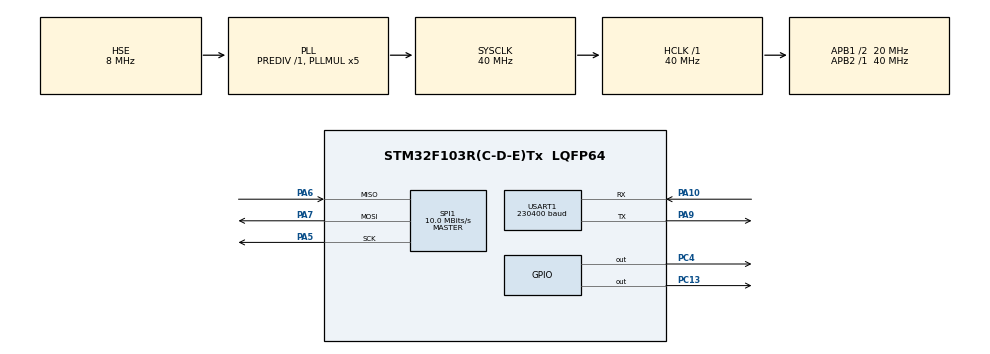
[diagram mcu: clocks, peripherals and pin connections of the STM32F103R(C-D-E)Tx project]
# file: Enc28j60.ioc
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Mcu.Family=STM32F1
Mcu.Name=STM32F103R(C-D-E)Tx
Mcu.Package=LQFP64
NVIC.PriorityGroup=NVIC_PRIORITYGROUP_4
NVIC.TIM2_IRQn=true\:0\:0\:false\:false\:true\:true\:true
NVIC.USART1_IRQn=true\:0\:0\:false\:false\:true\:true\:true
PA10.Mode=Asynchronous
PA10.Signal=USART1_RX
PA13.Mode=Serial_Wire
PA13.Signal=SYS_JTMS-SWDIO
PA14.Mode=Serial_Wire
PA14.Signal=SYS_JTCK-SWCLK
PA5.Mode=Full_Duplex_Master
PA5.Signal=SPI1_SCK
PA6.Mode=Full_Duplex_Master
PA6.Signal=SPI1_MISO
PA7.Mode=Full_Duplex_Master
PA7.Signal=SPI1_MOSI
PA9.Mode=Asynchronous
PA9.Signal=USART1_TX
PC13-TAMPER-RTC.GPIO_Speed=GPIO_SPEED_FREQ_MEDIUM
PC13-TAMPER-RTC.Signal=GPIO_Output
PC4.Signal=GPIO_Output
PD0-OSC_IN.Mode=HSE-External-Oscillator
PD0-OSC_IN.Signal=RCC_OSC_IN
PD1-OSC_OUT.Mode=HSE-External-Oscillator
PD1-OSC_OUT.Signal=RCC_OSC_OUT
ProjectManager.HeapSize=0x200
ProjectManager.StackSize=0x400
ProjectManager.TargetToolchain=MDK-ARM V5.27
RCC.AHBFreq_Value=40000000
RCC.APB1CLKDivider=RCC_HCLK_DIV2
RCC.APB1Freq_Value=20000000
RCC.APB1TimFreq_Value=40000000
RCC.APB2Freq_Value=40000000
RCC.APB2TimFreq_Value=40000000
RCC.HCLKFreq_Value=40000000
RCC.PLLMUL=RCC_PLL_MUL5
RCC.PLLSourceVirtual=RCC_PLLSOURCE_HSE
RCC.SYSCLKFreq_VALUE=40000000
RCC.SYSCLKSource=RCC_SYSCLKSOURCE_PLLCLK
RCC.USBFreq_Value=40000000
SPI1.BaudRatePrescaler=SPI_BAUDRATEPRESCALER_4
SPI1.CalculateBaudRate=10.0 MBits/s
SPI1.Direction=SPI_DIRECTION_2LINES
SPI1.Mode=SPI_MODE_MASTER
SPI1.VirtualType=VM_MASTER
TIM2.Period=1000
TIM2.Prescaler=39999
TIM2.TIM_MasterOutputTrigger=TIM_TRGO_UPDATE
USART1.BaudRate=230400
USART1.VirtualMode=VM_ASYNC
VP_TIM2_VS_ClockSourceINT.Mode=Internal
board=custom

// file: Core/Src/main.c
/* USER CODE BEGIN Header */
/**
  ******************************************************************************
  * @file           : main.c
  * @brief          : Main program body
  ******************************************************************************
  * @attention
  *
  * <h2><center>&copy; Copyright (c) 2021 STMicroelectronics.
  * All rights reserved.</center></h2>
  *
  * This software component is licensed by ST under BSD 3-Clause license,
  * the "License"; You may not use this file except in compliance with the
  * License. You may obtain a copy of the License at:
  *                        opensource.org/licenses/BSD-3-Clause
  *
  ******************************************************************************
  */
/* USER CODE END Header */
#include "main.h"

/* USER CODE BEGIN Includes */
#include "net.h"
#include "enc28j60.h"
/* USER CODE END Includes */

SPI_HandleTypeDef hspi1;

TIM_HandleTypeDef htim2;

UART_HandleTypeDef huart1;

/* USER CODE BEGIN PV */
char str[20];
/* USER CODE END PV */

void SystemClock_Config(void);
static void MX_GPIO_Init(void);
static void MX_SPI1_Init(void);
static void MX_USART1_UART_Init(void);
static void MX_TIM2_Init(void);

int main(void)
{

  /* MCU Configuration--------------------------------------------------------*/

  /* Reset of all peripherals, Initializes the Flash interface and the Systick. */
  HAL_Init();

  /* Configure the system clock */
  SystemClock_Config();

  /* Initialize all configured peripherals */
  MX_GPIO_Init();
  MX_SPI1_Init();
  MX_USART1_UART_Init();
  MX_TIM2_Init();
  /* USER CODE BEGIN 2 */
	net_ini();
	HAL_UART_Receive_IT(&huart1,(uint8_t*)str,1);
	HAL_TIM_Base_Start_IT(&htim2);
  /* USER CODE END 2 */

  /* Infinite loop */
  /* USER CODE BEGIN WHILE */
  while (1)
  {
		net_pool();
    /* USER CODE END WHILE */

  }
}

void SystemClock_Config(void)
{
  RCC_OscInitTypeDef RCC_OscInitStruct = {0};
  RCC_ClkInitTypeDef RCC_ClkInitStruct = {0};

  /** Initializes the RCC Oscillators according to the specified parameters
  * in the RCC_OscInitTypeDef structure.
  */
  RCC_OscInitStruct.OscillatorType = RCC_OSCILLATORTYPE_HSE;
  RCC_OscInitStruct.HSEState = RCC_HSE_ON;
  RCC_OscInitStruct.HSEPredivValue = RCC_HSE_PREDIV_DIV1;
  RCC_OscInitStruct.HSIState = RCC_HSI_ON;
  RCC_OscInitStruct.PLL.PLLState = RCC_PLL_ON;
  RCC_OscInitStruct.PLL.PLLSource = RCC_PLLSOURCE_HSE;
  RCC_OscInitStruct.PLL.PLLMUL = RCC_PLL_MUL5;
  if (HAL_RCC_OscConfig(&RCC_OscInitStruct) != HAL_OK)
  {
    Error_Handler();
  }
  /** Initializes the CPU, AHB and APB buses clocks
  */
  RCC_ClkInitStruct.ClockType = RCC_CLOCKTYPE_HCLK|RCC_CLOCKTYPE_SYSCLK
                              |RCC_CLOCKTYPE_PCLK1|RCC_CLOCKTYPE_PCLK2;
  RCC_ClkInitStruct.SYSCLKSource = RCC_SYSCLKSOURCE_PLLCLK;
  RCC_ClkInitStruct.AHBCLKDivider = RCC_SYSCLK_DIV1;
  RCC_ClkInitStruct.APB1CLKDivider = RCC_HCLK_DIV2;
  RCC_ClkInitStruct.APB2CLKDivider = RCC_HCLK_DIV1;

  if (HAL_RCC_ClockConfig(&RCC_ClkInitStruct, FLASH_LATENCY_1) != HAL_OK)
  {
    Error_Handler();
  }
}

static void MX_SPI1_Init(void)
{

  /* SPI1 parameter configuration*/
  hspi1.Instance = SPI1;
  hspi1.Init.Mode = SPI_MODE_MASTER;
  hspi1.Init.Direction = SPI_DIRECTION_2LINES;
  hspi1.Init.DataSize = SPI_DATASIZE_8BIT;
  hspi1.Init.CLKPolarity = SPI_POLARITY_LOW;
  hspi1.Init.CLKPhase = SPI_PHASE_1EDGE;
  hspi1.Init.NSS = SPI_NSS_SOFT;
  hspi1.Init.BaudRatePrescaler = SPI_BAUDRATEPRESCALER_4;
  hspi1.Init.FirstBit = SPI_FIRSTBIT_MSB;
  hspi1.Init.TIMode = SPI_TIMODE_DISABLE;
  hspi1.Init.CRCCalculation = SPI_CRCCALCULATION_DISABLE;
  hspi1.Init.CRCPolynomial = 10;
  if (HAL_SPI_Init(&hspi1) != HAL_OK)
  {
    Error_Handler();
  }

}

static void MX_TIM2_Init(void)
{

  TIM_ClockConfigTypeDef sClockSourceConfig = {0};
  TIM_MasterConfigTypeDef sMasterConfig = {0};

  htim2.Instance = TIM2;
  htim2.Init.Prescaler = 39999;
  htim2.Init.CounterMode = TIM_COUNTERMODE_UP;
  htim2.Init.Period = 1000;
  htim2.Init.ClockDivision = TIM_CLOCKDIVISION_DIV1;
  htim2.Init.AutoReloadPreload = TIM_AUTORELOAD_PRELOAD_DISABLE;
  if (HAL_TIM_Base_Init(&htim2) != HAL_OK)
  {
    Error_Handler();
  }
  sClockSourceConfig.ClockSource = TIM_CLOCKSOURCE_INTERNAL;
  if (HAL_TIM_ConfigClockSource(&htim2, &sClockSourceConfig) != HAL_OK)
  {
    Error_Handler();
  }
  sMasterConfig.MasterOutputTrigger = TIM_TRGO_UPDATE;
  sMasterConfig.MasterSlaveMode = TIM_MASTERSLAVEMODE_DISABLE;
  if (HAL_TIMEx_MasterConfigSynchronization(&htim2, &sMasterConfig) != HAL_OK)
  {
    Error_Handler();
  }

}

static void MX_USART1_UART_Init(void)
{

  huart1.Instance = USART1;
  huart1.Init.BaudRate = 230400;
  huart1.Init.WordLength = UART_WORDLENGTH_8B;
  huart1.Init.StopBits = UART_STOPBITS_1;
  huart1.Init.Parity = UART_PARITY_NONE;
  huart1.Init.Mode = UART_MODE_TX_RX;
  huart1.Init.HwFlowCtl = UART_HWCONTROL_NONE;
  huart1.Init.OverSampling = UART_OVERSAMPLING_16;
  if (HAL_UART_Init(&huart1) != HAL_OK)
  {
    Error_Handler();
  }

}

static void MX_GPIO_Init(void)
{
  GPIO_InitTypeDef GPIO_InitStruct = {0};

  /* GPIO Ports Clock Enable */
  __HAL_RCC_GPIOC_CLK_ENABLE();
  __HAL_RCC_GPIOD_CLK_ENABLE();
  __HAL_RCC_GPIOA_CLK_ENABLE();

  /*Configure GPIO pin Output Level */
  HAL_GPIO_WritePin(GPIOC, GPIO_PIN_13|GPIO_PIN_4, GPIO_PIN_RESET);

  /*Configure GPIO pin : PC13 */
  GPIO_InitStruct.Pin = GPIO_PIN_13;
  GPIO_InitStruct.Mode = GPIO_MODE_OUTPUT_PP;
  GPIO_InitStruct.Pull = GPIO_NOPULL;
  GPIO_InitStruct.Speed = GPIO_SPEED_FREQ_MEDIUM;
  HAL_GPIO_Init(GPIOC, &GPIO_InitStruct);

  /*Configure GPIO pin : PC4 */
  GPIO_InitStruct.Pin = GPIO_PIN_4;
  GPIO_InitStruct.Mode = GPIO_MODE_OUTPUT_PP;
  GPIO_InitStruct.Pull = GPIO_NOPULL;
  GPIO_InitStruct.Speed = GPIO_SPEED_FREQ_LOW;
  HAL_GPIO_Init(GPIOC, &GPIO_InitStruct);

}

/* USER CODE BEGIN 4 */
//--------------------------------------------------
void HAL_UART_RxCpltCallback(UART_HandleTypeDef *huart)
{
  if(huart==&huart1)
  {
    UART1_RxCpltCallback();
  }
}
//--------------------------------------------------
void HAL_TIM_PeriodElapsedCallback(TIM_HandleTypeDef *htim)
{
  if(htim==&htim2)
  {
    TIM_PeriodElapsedCallback();
  }
}
//--------------------------------------------------
/* USER CODE END 4 */

void Error_Handler(void)
{
  __disable_irq();
  while (1)
  {
  }
}

/************************ (C) COPYRIGHT STMicroelectronics *****END OF FILE****/
